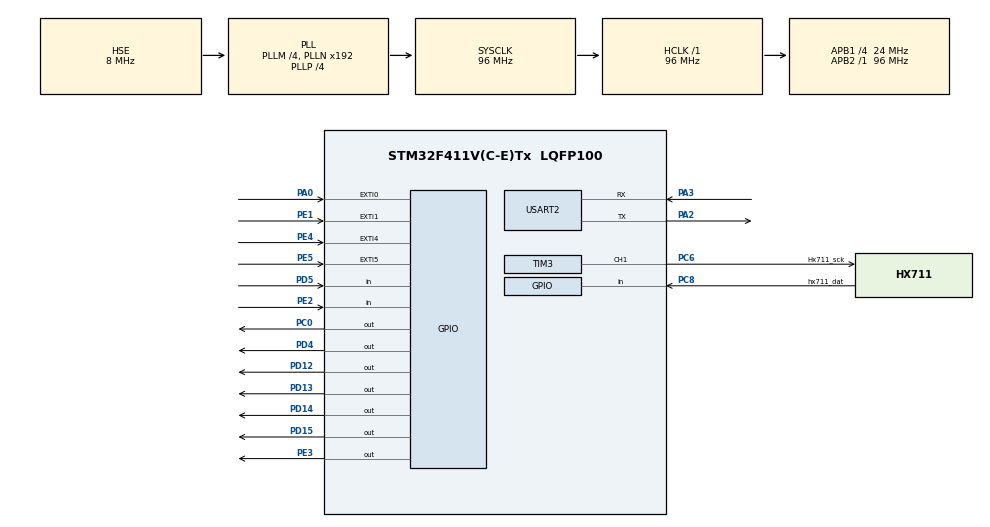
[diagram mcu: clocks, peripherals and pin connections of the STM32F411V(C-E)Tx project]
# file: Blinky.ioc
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Mcu.Family=STM32F4
Mcu.Name=STM32F411V(C-E)Tx
Mcu.Package=LQFP100
NVIC.EXTI0_IRQn=true\:0\:0\:false\:false\:true\:true\:true
NVIC.PriorityGroup=NVIC_PRIORITYGROUP_0
PA0-WKUP.GPIO_ModeDefaultEXTI=GPIO_MODE_IT_RISING
PA0-WKUP.GPIO_PuPd=GPIO_NOPULL
PA0-WKUP.Signal=GPXTI0
PA10.GPIO_PuPd=GPIO_PULLUP
PA10.Signal=USART1_RX
PA13.Signal=SYS_JTMS-SWDIO
PA14.Signal=SYS_JTCK-SWCLK
PA2.GPIO_PuPd=GPIO_PULLUP
PA2.Mode=Asynchronous
PA2.Signal=USART2_TX
PA3.GPIO_PuPd=GPIO_PULLUP
PA3.Mode=Asynchronous
PA3.Signal=USART2_RX
PA4.GPIO_Mode=GPIO_MODE_AF_PP
PA4.GPIO_PuPd=GPIO_NOPULL
PA4.GPIO_Speed=GPIO_SPEED_FREQ_LOW
PA4.Signal=I2S3_WS
PA5.GPIO_Mode=GPIO_MODE_AF_PP
PA5.GPIO_PuPd=GPIO_NOPULL
PA5.GPIO_Speed=GPIO_SPEED_FREQ_VERY_HIGH
PA5.Signal=SPI1_SCK
PA6.GPIO_Mode=GPIO_MODE_AF_PP
PA6.GPIO_PuPd=GPIO_NOPULL
PA6.GPIO_Speed=GPIO_SPEED_FREQ_VERY_HIGH
PA6.Signal=SPI1_MISO
PA7.GPIO_Mode=GPIO_MODE_AF_PP
PA7.GPIO_PuPd=GPIO_NOPULL
PA7.GPIO_Speed=GPIO_SPEED_FREQ_VERY_HIGH
PA7.Signal=SPI1_MOSI
PA9.GPIO_PuPd=GPIO_PULLUP
PA9.Signal=USART1_TX
PB10.GPIO_Mode=GPIO_MODE_AF_PP
PB10.GPIO_PuPd=GPIO_NOPULL
PB10.GPIO_Speed=GPIO_SPEED_FREQ_LOW
PB10.Signal=I2S2_CK
PB12.Signal=I2S2_WS
PB3.Signal=SYS_JTDO-SWO
PB6.GPIO_Mode=GPIO_MODE_AF_OD
PB6.GPIO_PuPd=GPIO_NOPULL
PB6.GPIO_PuPdOD=GPIO_PULLUP
PB6.GPIO_Speed=GPIO_SPEED_FREQ_VERY_HIGH
PB6.Signal=I2C1_SCL
PB9.GPIO_Mode=GPIO_MODE_AF_OD
PB9.GPIO_PuPd=GPIO_NOPULL
PB9.GPIO_PuPdOD=GPIO_PULLUP
PB9.GPIO_Speed=GPIO_SPEED_FREQ_VERY_HIGH
PB9.Signal=I2C1_SDA
PC0.GPIO_ModeDefaultOutputPP=GPIO_MODE_OUTPUT_PP
PC0.GPIO_PuPd=GPIO_NOPULL
PC0.GPIO_Speed=GPIO_SPEED_FREQ_LOW
PC0.PinState=GPIO_PIN_RESET
PC0.Signal=GPIO_Output
PC10.GPIO_Mode=GPIO_MODE_AF_PP
PC10.GPIO_PuPd=GPIO_NOPULL
PC10.GPIO_Speed=GPIO_SPEED_FREQ_LOW
PC10.Signal=I2S3_CK
PC12.GPIO_Mode=GPIO_MODE_AF_PP
PC12.GPIO_PuPd=GPIO_NOPULL
PC12.GPIO_Speed=GPIO_SPEED_FREQ_LOW
PC12.Signal=I2S3_SD
PC14-OSC32_IN.Mode=LSE-External-Oscillator
PC14-OSC32_IN.Signal=RCC_OSC32_IN
PC15-OSC32_OUT.Mode=LSE-External-Oscillator
PC15-OSC32_OUT.Signal=RCC_OSC32_OUT
PC3.GPIO_Mode=GPIO_MODE_AF_PP
PC3.GPIO_PuPd=GPIO_NOPULL
PC3.GPIO_Speed=GPIO_SPEED_FREQ_LOW
PC3.Signal=I2S2_SD
PC6.GPIO_Label=Hx711_sck
PC6.Signal=S_TIM3_CH1
PC7.GPIO_Mode=GPIO_MODE_AF_PP
PC7.GPIO_PuPd=GPIO_NOPULL
PC7.GPIO_Speed=GPIO_SPEED_FREQ_LOW
PC7.Signal=I2S3_MCK
PC8.GPIO_Label=hx711_dat
PC8.GPIO_PuPd=GPIO_PULLUP
PC8.Signal=GPIO_Input
PD12.GPIO_ModeDefaultOutputPP=GPIO_MODE_OUTPUT_PP
PD12.GPIO_PuPd=GPIO_NOPULL
PD12.GPIO_Speed=GPIO_SPEED_FREQ_LOW
PD12.PinState=GPIO_PIN_RESET
PD12.Signal=GPIO_Output
PD13.GPIO_ModeDefaultOutputPP=GPIO_MODE_OUTPUT_PP
PD13.GPIO_PuPd=GPIO_NOPULL
PD13.GPIO_Speed=GPIO_SPEED_FREQ_LOW
PD13.PinState=GPIO_PIN_RESET
PD13.Signal=GPIO_Output
PD14.GPIO_ModeDefaultOutputPP=GPIO_MODE_OUTPUT_PP
PD14.GPIO_PuPd=GPIO_NOPULL
PD14.GPIO_Speed=GPIO_SPEED_FREQ_LOW
PD14.PinState=GPIO_PIN_RESET
PD14.Signal=GPIO_Output
PD15.GPIO_ModeDefaultOutputPP=GPIO_MODE_OUTPUT_PP
PD15.GPIO_PuPd=GPIO_NOPULL
PD15.GPIO_Speed=GPIO_SPEED_FREQ_LOW
PD15.PinState=GPIO_PIN_RESET
PD15.Signal=GPIO_Output
PD4.GPIO_ModeDefaultOutputPP=GPIO_MODE_OUTPUT_PP
PD4.GPIO_PuPd=GPIO_NOPULL
PD4.GPIO_Speed=GPIO_SPEED_FREQ_LOW
PD4.PinState=GPIO_PIN_RESET
PD4.Signal=GPIO_Output
PD5.GPIO_Mode=GPIO_MODE_INPUT
PD5.GPIO_PuPd=GPIO_NOPULL
PD5.Signal=GPIO_Input
PE1.GPIO_ModeDefaultEXTI=GPIO_MODE_IT_RISING
PE1.GPIO_PuPd=GPIO_NOPULL
PE1.Signal=GPXTI1
PE2.GPIO_Mode=GPIO_MODE_INPUT
PE2.GPIO_PuPd=GPIO_NOPULL
PE2.Signal=GPIO_Input
PE3.Signal=GPIO_Output
PE4.GPIO_ModeDefaultEXTI=GPIO_MODE_IT_RISING
PE4.GPIO_PuPd=GPIO_NOPULL
PE4.Signal=GPXTI4
PE5.GPIO_ModeDefaultEXTI=GPIO_MODE_IT_RISING
PE5.GPIO_PuPd=GPIO_NOPULL
PE5.Signal=GPXTI5
PH0\ -\ OSC_IN.Mode=HSE-External-Oscillator
PH0\ -\ OSC_IN.Signal=RCC_OSC_IN
PH1\ -\ OSC_OUT.Mode=HSE-External-Oscillator
PH1\ -\ OSC_OUT.Signal=RCC_OSC_OUT
ProjectManager.HeapSize=0x200
ProjectManager.StackSize=0x400
ProjectManager.TargetToolchain=EWARM V8.32
RCC.48MHZClocksFreq_Value=48000000
RCC.AHBFreq_Value=96000000
RCC.APB1CLKDivider=RCC_HCLK_DIV4
RCC.APB1Freq_Value=24000000
RCC.APB1TimFreq_Value=48000000
RCC.APB2Freq_Value=96000000
RCC.APB2TimFreq_Value=96000000
RCC.CortexFreq_Value=96000000
RCC.HCLKFreq_Value=96000000
RCC.HSE_VALUE=8000000
RCC.HSI_VALUE=16000000
RCC.PLLI2SM=5
RCC.PLLI2SN=200
RCC.PLLM=4
RCC.PLLP=RCC_PLLP_DIV4
RCC.PLLQ=8
RCC.PLLSourceVirtual=RCC_PLLSOURCE_HSE
RCC.SYSCLKFreq_VALUE=96000000
RCC.SYSCLKSource=RCC_SYSCLKSOURCE_PLLCLK
RCC.VCOOutputFreq_Value=384000000
SH.S_TIM3_CH1.0=TIM3_CH1,PWM Generation1 CH1
TIM3.Channel-PWM\ Generation1\ CH1=TIM_CHANNEL_1
USART2.VirtualMode=VM_ASYNC
VP_RTC_VS_RTC_Activate.Mode=RTC_Enabled
VP_TIM1_VS_ClockSourceINT.Mode=Internal
VP_TIM1_VS_ClockSourceITR.Mode=TriggerSource_ITR0
VP_TIM3_VS_ClockSourceINT.Mode=Internal
board=STM32F411E-DISCO

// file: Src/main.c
/* USER CODE BEGIN Header */
/**
  ******************************************************************************
  * @file           : main.c
  * @brief          : Main program body
  ******************************************************************************
  * @attention
  *
  * <h2><center>&copy; Copyright (c) 2022 STMicroelectronics.
  * All rights reserved.</center></h2>
  *
  * This software component is licensed by ST under Ultimate Liberty license
  * SLA0044, the "License"; You may not use this file except in compliance with
  * the License. You may obtain a copy of the License at:
  *                             www.st.com/SLA0044
  *
  ******************************************************************************
  */
/* USER CODE END Header */

#include "main.h"

/* USER CODE BEGIN Includes */
#include "UI.h"
#include "console.h"
#include "hx711.h"
#include <stdint.h>
/* USER CODE END Includes */

RTC_HandleTypeDef hrtc;

TIM_HandleTypeDef htim1;
TIM_HandleTypeDef htim3;

UART_HandleTypeDef huart2;

void SystemClock_Config(void);
static void MX_GPIO_Init(void);
static void MX_RTC_Init(void);
static void MX_TIM1_Init(void);
static void MX_USART2_UART_Init(void);
static void MX_TIM3_Init(void);

int main(void)
{

  /* MCU Configuration--------------------------------------------------------*/

  /* Reset of all peripherals, Initializes the Flash interface and the Systick. */
  HAL_Init();

  /* Configure the system clock */
  SystemClock_Config();

  /* Initialize all configured peripherals */
  MX_GPIO_Init();
  MX_RTC_Init();
  MX_TIM1_Init();
  MX_USART2_UART_Init();
  MX_TIM3_Init();
  /* USER CODE BEGIN 2 */
  ConsoleInit();
  hx711_Init();
  /* USER CODE END 2 */

  /* Infinite loop */
  while (1)
  {

    /* USER CODE BEGIN 3 */
    UI_Run();
    ConsoleProcess();
    hx711_Run();
  }
  /* USER CODE END 3 */
}

void SystemClock_Config(void)
{
  RCC_OscInitTypeDef RCC_OscInitStruct = {0};
  RCC_ClkInitTypeDef RCC_ClkInitStruct = {0};
  RCC_PeriphCLKInitTypeDef PeriphClkInitStruct = {0};

  /** Configure the main internal regulator output voltage
  */
  __HAL_RCC_PWR_CLK_ENABLE();
  __HAL_PWR_VOLTAGESCALING_CONFIG(PWR_REGULATOR_VOLTAGE_SCALE1);
  /** Initializes the CPU, AHB and APB busses clocks
  */
  RCC_OscInitStruct.OscillatorType = RCC_OSCILLATORTYPE_LSI|RCC_OSCILLATORTYPE_HSE;
  RCC_OscInitStruct.HSEState = RCC_HSE_ON;
  RCC_OscInitStruct.LSIState = RCC_LSI_ON;
  RCC_OscInitStruct.PLL.PLLState = RCC_PLL_ON;
  RCC_OscInitStruct.PLL.PLLSource = RCC_PLLSOURCE_HSE;
  RCC_OscInitStruct.PLL.PLLM = 4;
  RCC_OscInitStruct.PLL.PLLN = 192;
  RCC_OscInitStruct.PLL.PLLP = RCC_PLLP_DIV4;
  RCC_OscInitStruct.PLL.PLLQ = 8;
  if (HAL_RCC_OscConfig(&RCC_OscInitStruct) != HAL_OK)
  {
    Error_Handler();
  }
  /** Initializes the CPU, AHB and APB busses clocks
  */
  RCC_ClkInitStruct.ClockType = RCC_CLOCKTYPE_HCLK|RCC_CLOCKTYPE_SYSCLK
                              |RCC_CLOCKTYPE_PCLK1|RCC_CLOCKTYPE_PCLK2;
  RCC_ClkInitStruct.SYSCLKSource = RCC_SYSCLKSOURCE_PLLCLK;
  RCC_ClkInitStruct.AHBCLKDivider = RCC_SYSCLK_DIV1;
  RCC_ClkInitStruct.APB1CLKDivider = RCC_HCLK_DIV4;
  RCC_ClkInitStruct.APB2CLKDivider = RCC_HCLK_DIV1;

  if (HAL_RCC_ClockConfig(&RCC_ClkInitStruct, FLASH_LATENCY_3) != HAL_OK)
  {
    Error_Handler();
  }
  PeriphClkInitStruct.PeriphClockSelection = RCC_PERIPHCLK_RTC;
  PeriphClkInitStruct.RTCClockSelection = RCC_RTCCLKSOURCE_LSI;
  if (HAL_RCCEx_PeriphCLKConfig(&PeriphClkInitStruct) != HAL_OK)
  {
    Error_Handler();
  }
}

static void MX_RTC_Init(void)
{

  /** Initialize RTC Only
  */
  hrtc.Instance = RTC;
  hrtc.Init.HourFormat = RTC_HOURFORMAT_24;
  hrtc.Init.AsynchPrediv = 127;
  hrtc.Init.SynchPrediv = 255;
  hrtc.Init.OutPut = RTC_OUTPUT_DISABLE;
  hrtc.Init.OutPutPolarity = RTC_OUTPUT_POLARITY_HIGH;
  hrtc.Init.OutPutType = RTC_OUTPUT_TYPE_OPENDRAIN;
  if (HAL_RTC_Init(&hrtc) != HAL_OK)
  {
    Error_Handler();
  }

}

static void MX_TIM1_Init(void)
{

  TIM_ClockConfigTypeDef sClockSourceConfig = {0};
  TIM_SlaveConfigTypeDef sSlaveConfig = {0};
  TIM_MasterConfigTypeDef sMasterConfig = {0};

  htim1.Instance = TIM1;
  htim1.Init.Prescaler = 0;
  htim1.Init.CounterMode = TIM_COUNTERMODE_UP;
  htim1.Init.Period = 0;
  htim1.Init.ClockDivision = TIM_CLOCKDIVISION_DIV1;
  htim1.Init.RepetitionCounter = 0;
  htim1.Init.AutoReloadPreload = TIM_AUTORELOAD_PRELOAD_DISABLE;
  if (HAL_TIM_Base_Init(&htim1) != HAL_OK)
  {
    Error_Handler();
  }
  sClockSourceConfig.ClockSource = TIM_CLOCKSOURCE_INTERNAL;
  if (HAL_TIM_ConfigClockSource(&htim1, &sClockSourceConfig) != HAL_OK)
  {
    Error_Handler();
  }
  sSlaveConfig.SlaveMode = TIM_SLAVEMODE_DISABLE;
  sSlaveConfig.InputTrigger = TIM_TS_ITR0;
  if (HAL_TIM_SlaveConfigSynchro(&htim1, &sSlaveConfig) != HAL_OK)
  {
    Error_Handler();
  }
  sMasterConfig.MasterOutputTrigger = TIM_TRGO_RESET;
  sMasterConfig.MasterSlaveMode = TIM_MASTERSLAVEMODE_DISABLE;
  if (HAL_TIMEx_MasterConfigSynchronization(&htim1, &sMasterConfig) != HAL_OK)
  {
    Error_Handler();
  }

}

static void MX_TIM3_Init(void)
{

  TIM_SlaveConfigTypeDef sSlaveConfig = {0};
  TIM_MasterConfigTypeDef sMasterConfig = {0};

  htim3.Instance = TIM3;
  htim3.Init.Prescaler = 0;
  htim3.Init.CounterMode = TIM_COUNTERMODE_UP;
  htim3.Init.Period = 0;
  htim3.Init.ClockDivision = TIM_CLOCKDIVISION_DIV1;
  htim3.Init.AutoReloadPreload = TIM_AUTORELOAD_PRELOAD_DISABLE;
  if (HAL_TIM_Base_Init(&htim3) != HAL_OK)
  {
    Error_Handler();
  }
  sSlaveConfig.SlaveMode = TIM_SLAVEMODE_DISABLE;
  sSlaveConfig.InputTrigger = TIM_TS_ITR0;
  if (HAL_TIM_SlaveConfigSynchro(&htim3, &sSlaveConfig) != HAL_OK)
  {
    Error_Handler();
  }
  sMasterConfig.MasterOutputTrigger = TIM_TRGO_RESET;
  sMasterConfig.MasterSlaveMode = TIM_MASTERSLAVEMODE_DISABLE;
  if (HAL_TIMEx_MasterConfigSynchronization(&htim3, &sMasterConfig) != HAL_OK)
  {
    Error_Handler();
  }

}

static void MX_USART2_UART_Init(void)
{

  huart2.Instance = USART2;
  huart2.Init.BaudRate = 115200;
  huart2.Init.WordLength = UART_WORDLENGTH_8B;
  huart2.Init.StopBits = UART_STOPBITS_1;
  huart2.Init.Parity = UART_PARITY_NONE;
  huart2.Init.Mode = UART_MODE_TX_RX;
  huart2.Init.HwFlowCtl = UART_HWCONTROL_NONE;
  huart2.Init.OverSampling = UART_OVERSAMPLING_16;
  if (HAL_UART_Init(&huart2) != HAL_OK)
  {
    Error_Handler();
  }

}

static void MX_GPIO_Init(void)
{
  GPIO_InitTypeDef GPIO_InitStruct = {0};

  /* GPIO Ports Clock Enable */
  __HAL_RCC_GPIOE_CLK_ENABLE();
  __HAL_RCC_GPIOC_CLK_ENABLE();
  __HAL_RCC_GPIOH_CLK_ENABLE();
  __HAL_RCC_GPIOA_CLK_ENABLE();
  __HAL_RCC_GPIOB_CLK_ENABLE();
  __HAL_RCC_GPIOD_CLK_ENABLE();

  /*Configure GPIO pin Output Level */
  HAL_GPIO_WritePin(GPIOE, GPIO_PIN_3, GPIO_PIN_RESET);

  /*Configure GPIO pin Output Level */
  HAL_GPIO_WritePin(GPIOC, GPIO_PIN_0|hx711_SCK_Pin, GPIO_PIN_RESET);

  /*Configure GPIO pin Output Level */
  HAL_GPIO_WritePin(GPIOD, GPIO_PIN_12|GPIO_PIN_13|GPIO_PIN_14|GPIO_PIN_15
                          |GPIO_PIN_4, GPIO_PIN_RESET);

  /*Configure GPIO pin : PE2 */
  GPIO_InitStruct.Pin = GPIO_PIN_2;
  GPIO_InitStruct.Mode = GPIO_MODE_INPUT;
  GPIO_InitStruct.Pull = GPIO_NOPULL;
  HAL_GPIO_Init(GPIOE, &GPIO_InitStruct);

  /*Configure GPIO pin : PE3 */
  GPIO_InitStruct.Pin = GPIO_PIN_3;
  GPIO_InitStruct.Mode = GPIO_MODE_OUTPUT_PP;
  GPIO_InitStruct.Pull = GPIO_NOPULL;
  GPIO_InitStruct.Speed = GPIO_SPEED_FREQ_LOW;
  HAL_GPIO_Init(GPIOE, &GPIO_InitStruct);

  /*Configure GPIO pins : PE4 PE5 PE1 */
  GPIO_InitStruct.Pin = GPIO_PIN_4|GPIO_PIN_5|GPIO_PIN_1;
  GPIO_InitStruct.Mode = GPIO_MODE_IT_RISING;
  GPIO_InitStruct.Pull = GPIO_NOPULL;
  HAL_GPIO_Init(GPIOE, &GPIO_InitStruct);

  /*Configure GPIO pins : PC0 hx711_SCK_Pin */
  GPIO_InitStruct.Pin = GPIO_PIN_0|hx711_SCK_Pin;
  GPIO_InitStruct.Mode = GPIO_MODE_OUTPUT_PP;
  GPIO_InitStruct.Pull = GPIO_NOPULL;
  GPIO_InitStruct.Speed = GPIO_SPEED_FREQ_VERY_HIGH;
  HAL_GPIO_Init(GPIOC, &GPIO_InitStruct);

  /*Configure GPIO pin : PC3 */
  GPIO_InitStruct.Pin = GPIO_PIN_3;
  GPIO_InitStruct.Mode = GPIO_MODE_AF_PP;
  GPIO_InitStruct.Pull = GPIO_NOPULL;
  GPIO_InitStruct.Speed = GPIO_SPEED_FREQ_LOW;
  GPIO_InitStruct.Alternate = GPIO_AF5_SPI2;
  HAL_GPIO_Init(GPIOC, &GPIO_InitStruct);

  /*Configure GPIO pin : PA0 */
  GPIO_InitStruct.Pin = GPIO_PIN_0;
  GPIO_InitStruct.Mode = GPIO_MODE_IT_RISING;
  GPIO_InitStruct.Pull = GPIO_NOPULL;
  HAL_GPIO_Init(GPIOA, &GPIO_InitStruct);

  /*Configure GPIO pin : PA4 */
  GPIO_InitStruct.Pin = GPIO_PIN_4;
  GPIO_InitStruct.Mode = GPIO_MODE_AF_PP;
  GPIO_InitStruct.Pull = GPIO_NOPULL;
  GPIO_InitStruct.Speed = GPIO_SPEED_FREQ_LOW;
  GPIO_InitStruct.Alternate = GPIO_AF6_SPI3;
  HAL_GPIO_Init(GPIOA, &GPIO_InitStruct);

  /*Configure GPIO pins : PA5 PA6 PA7 */
  GPIO_InitStruct.Pin = GPIO_PIN_5|GPIO_PIN_6|GPIO_PIN_7;
  GPIO_InitStruct.Mode = GPIO_MODE_AF_PP;
  GPIO_InitStruct.Pull = GPIO_NOPULL;
  GPIO_InitStruct.Speed = GPIO_SPEED_FREQ_VERY_HIGH;
  GPIO_InitStruct.Alternate = GPIO_AF5_SPI1;
  HAL_GPIO_Init(GPIOA, &GPIO_InitStruct);

  /*Configure GPIO pins : PB10 PB12 */
  GPIO_InitStruct.Pin = GPIO_PIN_10|GPIO_PIN_12;
  GPIO_InitStruct.Mode = GPIO_MODE_AF_PP;
  GPIO_InitStruct.Pull = GPIO_NOPULL;
  GPIO_InitStruct.Speed = GPIO_SPEED_FREQ_LOW;
  GPIO_InitStruct.Alternate = GPIO_AF5_SPI2;
  HAL_GPIO_Init(GPIOB, &GPIO_InitStruct);

  /*Configure GPIO pins : PD12 PD13 PD14 PD15
                           PD4 */
  GPIO_InitStruct.Pin = GPIO_PIN_12|GPIO_PIN_13|GPIO_PIN_14|GPIO_PIN_15
                          |GPIO_PIN_4;
  GPIO_InitStruct.Mode = GPIO_MODE_OUTPUT_PP;
  GPIO_InitStruct.Pull = GPIO_NOPULL;
  GPIO_InitStruct.Speed = GPIO_SPEED_FREQ_LOW;
  HAL_GPIO_Init(GPIOD, &GPIO_InitStruct);

  /*Configure GPIO pins : PC7 PC10 PC12 */
  GPIO_InitStruct.Pin = GPIO_PIN_7|GPIO_PIN_10|GPIO_PIN_12;
  GPIO_InitStruct.Mode = GPIO_MODE_AF_PP;
  GPIO_InitStruct.Pull = GPIO_NOPULL;
  GPIO_InitStruct.Speed = GPIO_SPEED_FREQ_LOW;
  GPIO_InitStruct.Alternate = GPIO_AF6_SPI3;
  HAL_GPIO_Init(GPIOC, &GPIO_InitStruct);

  /*Configure GPIO pin : hx711_Dat_Pin */
  GPIO_InitStruct.Pin = hx711_Dat_Pin;
  GPIO_InitStruct.Mode = GPIO_MODE_INPUT;
  GPIO_InitStruct.Pull = GPIO_NOPULL;
  GPIO_InitStruct.Speed = GPIO_SPEED_FREQ_VERY_HIGH;
  HAL_GPIO_Init(hx711_Dat_GPIO_Port, &GPIO_InitStruct);

  /*Configure GPIO pins : PA9 PA10 */
  GPIO_InitStruct.Pin = GPIO_PIN_9|GPIO_PIN_10;
  GPIO_InitStruct.Mode = GPIO_MODE_AF_PP;
  GPIO_InitStruct.Pull = GPIO_NOPULL;
  GPIO_InitStruct.Speed = GPIO_SPEED_FREQ_VERY_HIGH;
  GPIO_InitStruct.Alternate = GPIO_AF7_USART1;
  HAL_GPIO_Init(GPIOA, &GPIO_InitStruct);

  /*Configure GPIO pin : PD5 */
  GPIO_InitStruct.Pin = GPIO_PIN_5;
  GPIO_InitStruct.Mode = GPIO_MODE_INPUT;
  GPIO_InitStruct.Pull = GPIO_NOPULL;
  HAL_GPIO_Init(GPIOD, &GPIO_InitStruct);

  /*Configure GPIO pins : PB6 PB9 */
  GPIO_InitStruct.Pin = GPIO_PIN_6|GPIO_PIN_9;
  GPIO_InitStruct.Mode = GPIO_MODE_AF_OD;
  GPIO_InitStruct.Pull = GPIO_PULLUP;
  GPIO_InitStruct.Speed = GPIO_SPEED_FREQ_VERY_HIGH;
  GPIO_InitStruct.Alternate = GPIO_AF4_I2C1;
  HAL_GPIO_Init(GPIOB, &GPIO_InitStruct);

  /* EXTI interrupt init*/
  HAL_NVIC_SetPriority(EXTI0_IRQn, 0, 0);
  HAL_NVIC_EnableIRQ(EXTI0_IRQn);

}

/* USER CODE BEGIN 4 */
UART_HandleTypeDef * GetUART1Handle(void)
{
  return &huart2;
}
/* USER CODE END 4 */

void Error_Handler(void)
{
  /* USER CODE BEGIN Error_Handler_Debug */
  /* User can add her own implementation to report the HAL error return state */

  /* USER CODE END Error_Handler_Debug */
}

/************************ (C) COPYRIGHT STMicroelectronics *****END OF FILE****/
